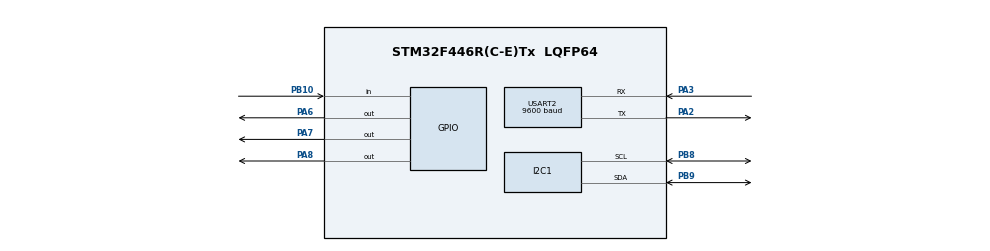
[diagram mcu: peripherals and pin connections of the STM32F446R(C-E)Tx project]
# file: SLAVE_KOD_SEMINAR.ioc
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I2C1.DualAddressMode=I2C_DUALADDRESS_DISABLE
I2C1.GeneralCallMode=I2C_GENERALCALL_ENABLE
I2C1.OwnAddress=80
Mcu.Family=STM32F4
Mcu.Name=STM32F446R(C-E)Tx
Mcu.Package=LQFP64
NVIC.PriorityGroup=NVIC_PRIORITYGROUP_4
PA13.Mode=Serial_Wire
PA13.Signal=SYS_JTMS-SWDIO
PA14.Mode=Serial_Wire
PA14.Signal=SYS_JTCK-SWCLK
PA2.Mode=Asynchronous
PA2.Signal=USART2_TX
PA3.Mode=Asynchronous
PA3.Signal=USART2_RX
PA6.Signal=GPIO_Output
PA7.Signal=GPIO_Output
PA8.Signal=GPIO_Output
PB10.GPIO_PuPd=GPIO_PULLUP
PB10.Signal=GPIO_Input
PB8.Mode=I2C
PB8.Signal=I2C1_SCL
PB9.Mode=I2C
PB9.Signal=I2C1_SDA
ProjectManager.HeapSize=0x200
ProjectManager.StackSize=0x400
ProjectManager.TargetToolchain=STM32CubeIDE
RCC.CortexFreq_Value=16000000
RCC.USBFreq_Value=96000000
RCC.VCOOutputFreq_Value=192000000
USART2.BaudRate=9600
USART2.VirtualMode=VM_ASYNC
board=custom

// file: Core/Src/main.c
/* USER CODE BEGIN Header */
/**
  ******************************************************************************
  * @file           : main.c
  * @brief          : Main program body
  ******************************************************************************
  * @attention
  *
  * Copyright (c) 2026 STMicroelectronics.
  * All rights reserved.
  *
  * This software is licensed under terms that can be found in the LICENSE file
  * in the root directory of this software component.
  * If no LICENSE file comes with this software, it is provided AS-IS.
  *
  ******************************************************************************
  */
/* USER CODE END Header */
#include "main.h"
#include "i2c.h"
#include "usart.h"
#include "gpio.h"
#include "liquidcrystal_i2c.h"

void SystemClock_Config(void);

/* USER CODE BEGIN 0 */
uint8_t p=0;
  uint8_t ok2=2;
/* USER CODE END 0 */

int main(void)
{

  /* MCU Configuration--------------------------------------------------------*/

  /* Reset of all peripherals, Initializes the Flash interface and the Systick. */
  HAL_Init();

  /* Configure the system clock */
  SystemClock_Config();

  /* Initialize all configured peripherals */
  MX_GPIO_Init();
  MX_I2C1_Init();
  MX_USART2_UART_Init();

  HD44780_Init(2);
  HD44780_NoDisplay();
  HD44780_Clear();
  HD44780_Display();
  HD44780_SetCursor(0,0);

  /* USER CODE BEGIN 2 */

  uint8_t data_in;
    while (1)
    {
      /* USER CODE END WHILE */
    	if (HAL_I2C_Slave_Receive(&hi2c1, &data_in, sizeof(data_in), HAL_MAX_DELAY) == HAL_OK)
    	    {
    		    ok2=data_in%10;
    			p=data_in/10;
    			if((p <= 12 && ok2==2) || (p <= 5 && ok2==1) )	{
    				HD44780_Display();
    				HD44780_SetCursor(0,0);
    				HD44780_PrintStr("Udaljenost:");

    							//HD44780_Clear();
    			  	    	  //HD44780_Display();
    	        if ((p <= 12 && p > 8 && ok2==2) || (p <= 5 && p > 4 && ok2==1))
    	        {
    	            // Button RELEASED: Turn PA6 ON, Turn PA8 OFF
    	            HAL_GPIO_WritePin(GPIOA, GPIO_PIN_6, GPIO_PIN_RESET);
    	            HAL_GPIO_WritePin(GPIOA, GPIO_PIN_7, GPIO_PIN_SET);
    	            HAL_GPIO_WritePin(GPIOA, GPIO_PIN_8, GPIO_PIN_RESET);
    	            HD44780_SetCursor(0,1);
    	            if(p/10==0){
    	            	HD44780_PrintSpecialChar(p+48);
    	            	HD44780_PrintSpecialChar(32);
    	            }
    	            	else {
    	            			HD44780_PrintSpecialChar((p/10)+48);
    	            			HD44780_PrintSpecialChar((p%10)+48);
    	            		 }
    	            if(ok2==2) HD44780_PrintStr("cm ");
    	            if(ok2==1) HD44780_PrintStr("in ");

    	        }
    	         if ((p <= 8 && p > 4 && ok2==2) || (p <= 4 && p > 2 && ok2==1))
    	        {
    	            // Button PRESSED: Turn PA6 OFF, Turn PA8 ON
    	            HAL_GPIO_WritePin(GPIOA, GPIO_PIN_6, GPIO_PIN_SET);
    	            HAL_GPIO_WritePin(GPIOA, GPIO_PIN_7, GPIO_PIN_RESET);
    	            HAL_GPIO_WritePin(GPIOA, GPIO_PIN_8, GPIO_PIN_RESET);
    	            HD44780_SetCursor(0,1);
    	            	HD44780_PrintSpecialChar(p+48);
        	            if(ok2==2) HD44780_PrintStr("cm ");
        	            if(ok2==1) HD44780_PrintStr("in ");
    	        }
    	         if ((p <=4  && p >= 1 && ok2==2) || (p <= 2 && p >= 1 && ok2==1))
    	            	        {
    	            	            // Button PRESSED: Turn PA6 OFF, Turn PA8 ON

    	            	            HAL_GPIO_WritePin(GPIOA, GPIO_PIN_6, GPIO_PIN_RESET);
    	            	            HAL_GPIO_WritePin(GPIOA, GPIO_PIN_7, GPIO_PIN_RESET);
    	            	            HAL_GPIO_WritePin(GPIOA, GPIO_PIN_8, GPIO_PIN_SET);
    	            	            HD44780_SetCursor(0,1);
    	            	            	HD44780_PrintSpecialChar(p+48);
    	                	            if(ok2==2) HD44780_PrintStr("cm ");
    	                	            if(ok2==1) HD44780_PrintStr("in ");
    	            	        }
    	         if (p < 1)
    	            	        {
    	            	            // Button PRESSED: Turn PA6 OFF, Turn PA8 ON
    	            	            HAL_GPIO_WritePin(GPIOA, GPIO_PIN_6, GPIO_PIN_RESET);
    	            	            HAL_GPIO_WritePin(GPIOA, GPIO_PIN_7, GPIO_PIN_RESET);
    	            	            HAL_GPIO_WritePin(GPIOA, GPIO_PIN_8, GPIO_PIN_SET);
    	            	            HD44780_SetCursor(0,1);
    	            	            HD44780_PrintStr("!!!!");
    	            	        }

    	    }	else {
	            // Button PRESSED: Turn PA6 OFF, Turn PA8 ON
	            HAL_GPIO_WritePin(GPIOA, GPIO_PIN_6, GPIO_PIN_RESET);
	            HAL_GPIO_WritePin(GPIOA, GPIO_PIN_7, GPIO_PIN_RESET);
	            HAL_GPIO_WritePin(GPIOA, GPIO_PIN_8, GPIO_PIN_RESET);
	            HD44780_Clear();
	        }

    }
  }
}

void SystemClock_Config(void)
{
  RCC_OscInitTypeDef RCC_OscInitStruct = {0};
  RCC_ClkInitTypeDef RCC_ClkInitStruct = {0};

  /** Configure the main internal regulator output voltage
  */
  __HAL_RCC_PWR_CLK_ENABLE();
  __HAL_PWR_VOLTAGESCALING_CONFIG(PWR_REGULATOR_VOLTAGE_SCALE3);

  /** Initializes the RCC Oscillators according to the specified parameters
  * in the RCC_OscInitTypeDef structure.
  */
  RCC_OscInitStruct.OscillatorType = RCC_OSCILLATORTYPE_HSI;
  RCC_OscInitStruct.HSIState = RCC_HSI_ON;
  RCC_OscInitStruct.HSICalibrationValue = RCC_HSICALIBRATION_DEFAULT;
  RCC_OscInitStruct.PLL.PLLState = RCC_PLL_NONE;
  if (HAL_RCC_OscConfig(&RCC_OscInitStruct) != HAL_OK)
  {
    Error_Handler();
  }

  /** Initializes the CPU, AHB and APB buses clocks
  */
  RCC_ClkInitStruct.ClockType = RCC_CLOCKTYPE_HCLK|RCC_CLOCKTYPE_SYSCLK
                              |RCC_CLOCKTYPE_PCLK1|RCC_CLOCKTYPE_PCLK2;
  RCC_ClkInitStruct.SYSCLKSource = RCC_SYSCLKSOURCE_HSI;
  RCC_ClkInitStruct.AHBCLKDivider = RCC_SYSCLK_DIV1;
  RCC_ClkInitStruct.APB1CLKDivider = RCC_HCLK_DIV1;
  RCC_ClkInitStruct.APB2CLKDivider = RCC_HCLK_DIV1;

  if (HAL_RCC_ClockConfig(&RCC_ClkInitStruct, FLASH_LATENCY_0) != HAL_OK)
  {
    Error_Handler();
  }
}

void Error_Handler(void)
{
  __disable_irq();
  while (1)
  {
  }
}
